AUTOSAR XML (schema 4-0-3)
package /ComponentTypes
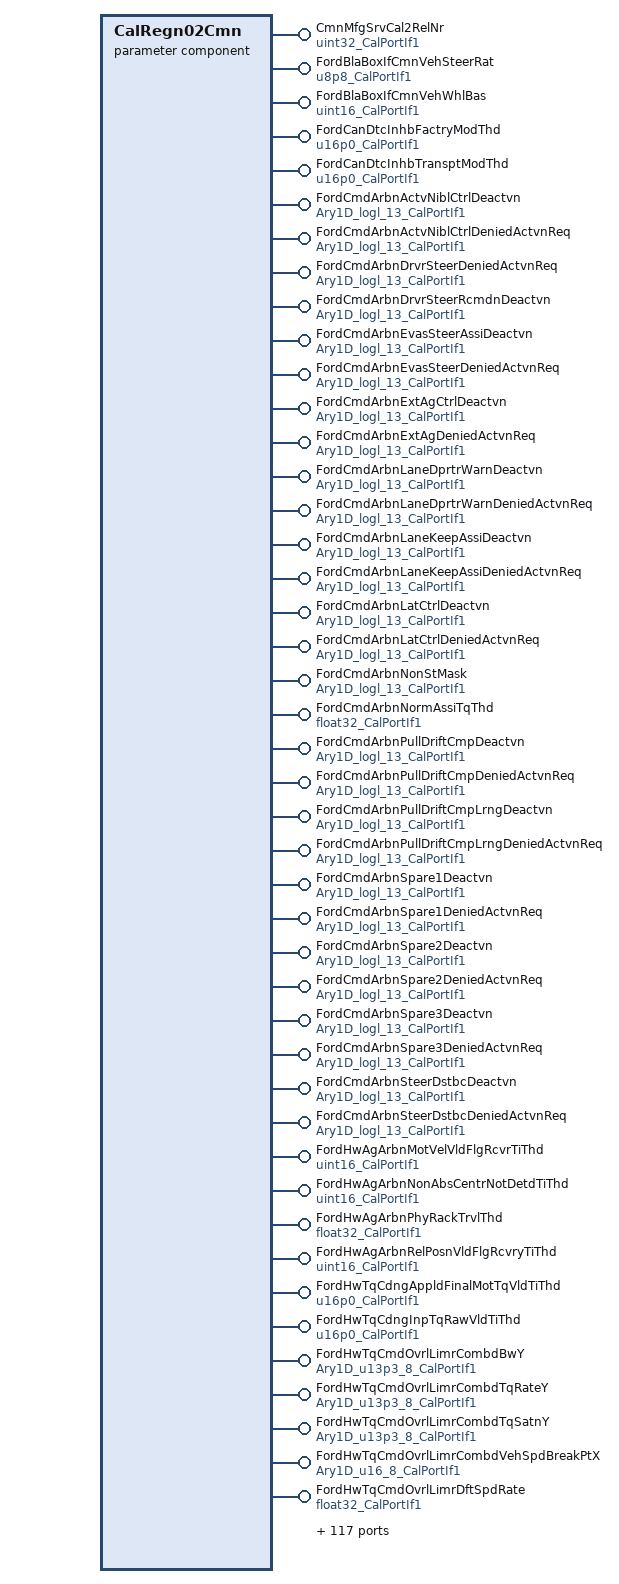
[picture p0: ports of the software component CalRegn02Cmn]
  parameter sw component type CalRegn02Cmn
    161 x provide port:
      CmnMfgSrvCal2RelNr: parameter-provide-com-spec{init-value=0, parameter=Val}, provided-interface=uint32_CalPortIf1
      FordBlaBoxIfCmnVehSteerRat: parameter-provide-com-spec{init-value=0, parameter=Val}, provided-interface=u8p8_CalPortIf1
      FordBlaBoxIfCmnVehWhlBas: parameter-provide-com-spec{init-value=3099, parameter=Val}, provided-interface=uint16_CalPortIf1
      FordCanDtcInhbFactryModThd: parameter-provide-com-spec{init-value=0, parameter=Val}, provided-interface=u16p0_CalPortIf1
      FordCanDtcInhbTransptModThd: parameter-provide-com-spec{init-value=0, parameter=Val}, provided-interface=u16p0_CalPortIf1
      FordCmdArbnActvNiblCtrlDeactvn: parameter-provide-com-spec{init-value=[1, 1, 1, 1, 1, 1, 1, 1, 1, 0, 0, 0, 0], parameter=Ary1D}, provided-interface=Ary1D_logl_13_CalPortIf1
      FordCmdArbnActvNiblCtrlDeniedActvnReq: parameter-provide-com-spec{init-value=[1, 1, 1, 1, 1, 1, 1, 1, 1, 0, 0, 0, 0], parameter=Ary1D}, provided-interface=Ary1D_logl_13_CalPortIf1
      FordCmdArbnDrvrSteerDeniedActvnReq: parameter-provide-com-spec{init-value=[0, 0, 0, 0, 0, 0, 1, 1, 1, 0, 0, 0, 0], parameter=Ary1D}, provided-interface=Ary1D_logl_13_CalPortIf1
      FordCmdArbnDrvrSteerRcmdnDeactvn: parameter-provide-com-spec{init-value=[1, 1, 1, 1, 1, 1, 1, 1, 1, 0, 0, 0, 0], parameter=Ary1D}, provided-interface=Ary1D_logl_13_CalPortIf1
      FordCmdArbnEvasSteerAssiDeactvn: parameter-provide-com-spec{init-value=[1, 1, 1, 1, 1, 1, 1, 1, 1, 0, 0, 0, 0], parameter=Ary1D}, provided-interface=Ary1D_logl_13_CalPortIf1
      FordCmdArbnEvasSteerDeniedActvnReq: parameter-provide-com-spec{init-value=[1, 1, 1, 1, 1, 1, 1, 1, 1, 0, 0, 0, 0], parameter=Ary1D}, provided-interface=Ary1D_logl_13_CalPortIf1
      FordCmdArbnExtAgCtrlDeactvn: parameter-provide-com-spec{init-value=[1, 1, 1, 1, 1, 1, 1, 1, 1, 1, 0, 0, 0], parameter=Ary1D}, provided-interface=Ary1D_logl_13_CalPortIf1
      FordCmdArbnExtAgDeniedActvnReq: parameter-provide-com-spec{init-value=[1, 1, 1, 1, 1, 1, 0, 0, 0, 1, 0, 0, 0], parameter=Ary1D}, provided-interface=Ary1D_logl_13_CalPortIf1
      FordCmdArbnLaneDprtrWarnDeactvn: parameter-provide-com-spec{init-value=[1, 1, 1, 1, 1, 1, 1, 1, 1, 0, 0, 0, 0], parameter=Ary1D}, provided-interface=Ary1D_logl_13_CalPortIf1
      FordCmdArbnLaneDprtrWarnDeniedActvnReq: parameter-provide-com-spec{init-value=[1, 1, 1, 1, 1, 1, 1, 1, 1, 0, 0, 0, 0], parameter=Ary1D}, provided-interface=Ary1D_logl_13_CalPortIf1
      FordCmdArbnLaneKeepAssiDeactvn: parameter-provide-com-spec{init-value=[1, 1, 1, 1, 1, 1, 1, 1, 1, 0, 0, 0, 0], parameter=Ary1D}, provided-interface=Ary1D_logl_13_CalPortIf1
      FordCmdArbnLaneKeepAssiDeniedActvnReq: parameter-provide-com-spec{init-value=[1, 1, 1, 1, 1, 1, 1, 1, 1, 0, 0, 0, 0], parameter=Ary1D}, provided-interface=Ary1D_logl_13_CalPortIf1
      FordCmdArbnLatCtrlDeactvn: parameter-provide-com-spec{init-value=13 x 0, parameter=Ary1D}, provided-interface=Ary1D_logl_13_CalPortIf1
      FordCmdArbnLatCtrlDeniedActvnReq: parameter-provide-com-spec{init-value=13 x 0, parameter=Ary1D}, provided-interface=Ary1D_logl_13_CalPortIf1
      FordCmdArbnNonStMask: parameter-provide-com-spec{init-value=[1, 1, 1, 0, 1, 1, 0, 1, 1, 1, 0, 0, 0], parameter=Ary1D}, provided-interface=Ary1D_logl_13_CalPortIf1
      FordCmdArbnNormAssiTqThd: parameter-provide-com-spec{init-value=0, parameter=Val}, provided-interface=float32_CalPortIf1
      FordCmdArbnPullDriftCmpDeactvn: parameter-provide-com-spec{init-value=[1, 1, 1, 1, 1, 1, 1, 1, 1, 0, 0, 0, 0], parameter=Ary1D}, provided-interface=Ary1D_logl_13_CalPortIf1
      FordCmdArbnPullDriftCmpDeniedActvnReq: parameter-provide-com-spec{init-value=[1, 1, 1, 1, 1, 1, 1, 1, 1, 0, 0, 0, 0], parameter=Ary1D}, provided-interface=Ary1D_logl_13_CalPortIf1
      FordCmdArbnPullDriftCmpLrngDeactvn: parameter-provide-com-spec{init-value=[1, 1, 1, 1, 0, 0, 0, 1, 1, 0, 0, 0, 0], parameter=Ary1D}, provided-interface=Ary1D_logl_13_CalPortIf1
      FordCmdArbnPullDriftCmpLrngDeniedActvnReq: parameter-provide-com-spec{init-value=[1, 1, 1, 1, 0, 0, 0, 1, 1, 0, 0, 0, 0], parameter=Ary1D}, provided-interface=Ary1D_logl_13_CalPortIf1
      FordCmdArbnSpare1Deactvn: parameter-provide-com-spec{init-value=[1, 1, 1, 1, 1, 1, 1, 1, 1, 0, 0, 0, 0], parameter=Ary1D}, provided-interface=Ary1D_logl_13_CalPortIf1
      FordCmdArbnSpare1DeniedActvnReq: parameter-provide-com-spec{init-value=[1, 1, 1, 1, 1, 1, 1, 1, 1, 0, 0, 0, 0], parameter=Ary1D}, provided-interface=Ary1D_logl_13_CalPortIf1
      FordCmdArbnSpare2Deactvn: parameter-provide-com-spec{init-value=[1, 1, 1, 1, 1, 1, 1, 1, 1, 0, 0, 0, 0], parameter=Ary1D}, provided-interface=Ary1D_logl_13_CalPortIf1
      FordCmdArbnSpare2DeniedActvnReq: parameter-provide-com-spec{init-value=[1, 1, 1, 1, 1, 1, 1, 1, 1, 0, 0, 0, 0], parameter=Ary1D}, provided-interface=Ary1D_logl_13_CalPortIf1
      FordCmdArbnSpare3Deactvn: parameter-provide-com-spec{init-value=[1, 1, 1, 1, 1, 1, 1, 1, 1, 0, 0, 0, 0], parameter=Ary1D}, provided-interface=Ary1D_logl_13_CalPortIf1
      FordCmdArbnSpare3DeniedActvnReq: parameter-provide-com-spec{init-value=[1, 1, 1, 1, 1, 1, 1, 1, 1, 0, 0, 0, 0], parameter=Ary1D}, provided-interface=Ary1D_logl_13_CalPortIf1
      FordCmdArbnSteerDstbcDeactvn: parameter-provide-com-spec{init-value=13 x 0, parameter=Ary1D}, provided-interface=Ary1D_logl_13_CalPortIf1
      FordCmdArbnSteerDstbcDeniedActvnReq: parameter-provide-com-spec{init-value=13 x 0, parameter=Ary1D}, provided-interface=Ary1D_logl_13_CalPortIf1
      FordHwAgArbnMotVelVldFlgRcvrTiThd: parameter-provide-com-spec{init-value=30000, parameter=Val}, provided-interface=uint16_CalPortIf1
      FordHwAgArbnNonAbsCentrNotDetdTiThd: parameter-provide-com-spec{init-value=30000, parameter=Val}, provided-interface=uint16_CalPortIf1
      FordHwAgArbnPhyRackTrvlThd: parameter-provide-com-spec{init-value=65535, parameter=Val}, provided-interface=float32_CalPortIf1
      FordHwAgArbnRelPosnVldFlgRcvryTiThd: parameter-provide-com-spec{init-value=0, parameter=Val}, provided-interface=uint16_CalPortIf1
      FordHwTqCdngAppldFinalMotTqVldTiThd: parameter-provide-com-spec{init-value=0, parameter=Val}, provided-interface=u16p0_CalPortIf1
      FordHwTqCdngInpTqRawVldTiThd: parameter-provide-com-spec{init-value=0, parameter=Val}, provided-interface=u16p0_CalPortIf1
      FordHwTqCmdOvrlLimrCombdBwY: parameter-provide-com-spec{init-value=8 x 0, parameter=Ary1D}, provided-interface=Ary1D_u13p3_8_CalPortIf1
      FordHwTqCmdOvrlLimrCombdTqRateY: parameter-provide-com-spec{init-value=8 x 64, parameter=Ary1D}, provided-interface=Ary1D_u13p3_8_CalPortIf1
      FordHwTqCmdOvrlLimrCombdTqSatnY: parameter-provide-com-spec{init-value=8 x 0, parameter=Ary1D}, provided-interface=Ary1D_u13p3_8_CalPortIf1
      FordHwTqCmdOvrlLimrCombdVehSpdBreakPtX: parameter-provide-com-spec{init-value=[0, 15, 60, 100, 150, 180, 200, 250], parameter=Ary1D}, provided-interface=Ary1D_u16_8_CalPortIf1
      FordHwTqCmdOvrlLimrDftSpdRate: parameter-provide-com-spec{init-value=40, parameter=Val}, provided-interface=float32_CalPortIf1
      FordHwTqCmdOvrlLimrDftSpdRcvrRate: parameter-provide-com-spec{init-value=40, parameter=Val}, provided-interface=float32_CalPortIf1
      FordHwTqCmdOvrlLimrLkaBwY: parameter-provide-com-spec{init-value=8 x 0, parameter=Ary1D}, provided-interface=Ary1D_u13p3_8_CalPortIf1
      FordHwTqCmdOvrlLimrLkaTqRateY: parameter-provide-com-spec{init-value=8 x 40, parameter=Ary1D}, provided-interface=Ary1D_u13p3_8_CalPortIf1
      FordHwTqCmdOvrlLimrLkaTqSatnY: parameter-provide-com-spec{init-value=8 x 0, parameter=Ary1D}, provided-interface=Ary1D_u13p3_8_CalPortIf1
      FordHwTqCmdOvrlLimrVehSpdBreakPtX: parameter-provide-com-spec{init-value=[0, 15, 60, 100, 150, 180, 200, 250], parameter=Ary1D}, provided-interface=Ary1D_u16_8_CalPortIf1
      FordMotTqCmdOvrlLimrDftSpdRate: parameter-provide-com-spec{init-value=40, parameter=Val}, provided-interface=float32_CalPortIf1
      FordMotTqCmdOvrlLimrDftSpdRcvrRate: parameter-provide-com-spec{init-value=40, parameter=Val}, provided-interface=float32_CalPortIf1
      FordMotTqCmdOvrlLimrHiFrqMonrActvNiblCtrlDcTqTrendThd: parameter-provide-com-spec{init-value=1, parameter=Val}, provided-interface=float32_CalPortIf1
      FordMotTqCmdOvrlLimrHiFrqMonrActvNiblCtrlLoFrqTiThd: parameter-provide-com-spec{init-value=0.1, parameter=Val}, provided-interface=float32_CalPortIf1
      FordMotTqCmdOvrlLimrHiFrqMonrActvNiblCtrlMaxMotTq: parameter-provide-com-spec{init-value=5, parameter=Val}, provided-interface=float32_CalPortIf1
      FordMotTqCmdOvrlLimrHiFrqMonrLaneDprtrWarnDcTqTrendThd: parameter-provide-com-spec{init-value=1.5, parameter=Val}, provided-interface=float32_CalPortIf1
      FordMotTqCmdOvrlLimrHiFrqMonrLaneDprtrWarnLoFrqTiThd: parameter-provide-com-spec{init-value=0.033, parameter=Val}, provided-interface=float32_CalPortIf1
      FordMotTqCmdOvrlLimrHiFrqMonrLaneDprtrWarnMaxMotTq: parameter-provide-com-spec{init-value=5.5, parameter=Val}, provided-interface=float32_CalPortIf1
      FordMotTqCmdOvrlLimrHiFrqMonrTqTrendAlpha: parameter-provide-com-spec{init-value=1, parameter=Val}, provided-interface=float32_CalPortIf1
      FordMotTqCmdOvrlLimrHiFrqMonrZeroBandTq: parameter-provide-com-spec{init-value=1, parameter=Val}, provided-interface=float32_CalPortIf1
      FordMotTqCmdOvrlLimrHwVelLoPassFrq: parameter-provide-com-spec{init-value=0, parameter=Val}, provided-interface=float32_CalPortIf1
      FordMotTqCmdOvrlLimrLatCtrlBwY: parameter-provide-com-spec=Val, provided-interface=Ary1D_s5p10_8_CalPortIf1
      FordMotTqCmdOvrlLimrLatCtrlTqRateY: parameter-provide-com-spec{init-value=8 x 5, parameter=Ary1D}, provided-interface=Ary1D_s16_8_CalPortIf1
      FordMotTqCmdOvrlLimrLatCtrlTqSatnY: parameter-provide-com-spec{init-value=8 x 0, parameter=Ary1D}, provided-interface=Ary1D_s16_8_CalPortIf1
      FordMotTqCmdOvrlLimrLatCtrlVehSpdBreakPtX: parameter-provide-com-spec{init-value=[0, 1920, 7680, 12800, 19200, 23040, 25600, 32000], parameter=Ary1D}, provided-interface=Ary1D_u9p7_8_CalPortIf1
      FordMotTqCmdOvrlLimrPullDriftCmpTqRateY: parameter-provide-com-spec{init-value=8 x 1, parameter=Ary1D}, provided-interface=Ary1D_s16_8_CalPortIf1
      FordMotTqCmdOvrlLimrPullDriftCmpTqSatnY: parameter-provide-com-spec{init-value=8 x 3, parameter=Ary1D}, provided-interface=Ary1D_s16_8_CalPortIf1
      FordMotTqCmdOvrlLimrPullDriftCmpVehSpdBreakPtX: parameter-provide-com-spec{init-value=[0, 15, 60, 100, 150, 180, 200, 250], parameter=Ary1D}, provided-interface=Ary1D_u16_8_CalPortIf1
      FordMotTqCmdOvrlLimrSteerReactnLimrCombAmpVehSpdLimX: parameter-provide-com-spec{init-value=8 x 0, parameter=Ary1D}, provided-interface=Ary1D_u16_8_CalPortIf1
      FordMotTqCmdOvrlLimrSteerReactnLimrCombAmpVehSpdLimY: parameter-provide-com-spec{init-value=[0, 15, 40, 70, 100, 150, 200, 250], parameter=Ary1D}, provided-interface=Ary1D_u16_8_CalPortIf1
      FordMotTqCmdOvrlLimrSteerReactnLimrCombdAmpOvrrun: parameter-provide-com-spec{init-value=0, parameter=Val}, provided-interface=float32_CalPortIf1
      FordMotTqCmdOvrlLimrSteerReactnLimrCombdAmpRcvry: parameter-provide-com-spec{init-value=0.5, parameter=Val}, provided-interface=float32_CalPortIf1
      FordMotTqCmdOvrlLimrSteerReactnLimrCombdFixdOvrrunRampRate: parameter-provide-com-spec{init-value=8, parameter=Val}, provided-interface=float32_CalPortIf1
      FordMotTqCmdOvrlLimrSteerReactnLimrCombdLimHys: parameter-provide-com-spec{init-value=0.05, parameter=Val}, provided-interface=float32_CalPortIf1
      FordMotTqCmdOvrlLimrSteerReactnLimrCombdLimrHwVelY: parameter-provide-com-spec{init-value=[[-20, 10, 20, 30, 80, 100, 100, 100, 100], [-20, 10, 20, 30, 80, 100, 100, 100, 100], [-20, 10, 20, 20, 80, 100, 100, 100, 100], [-20, 10, 20, 20, 80, 100, 100, 100, 100], [-40, 5, 10, 15, 60, 80, 80, 80, 80], [-40, 0, 5, 10, 30, 40, 40, 40, 40], [-40, 0, 5, 10, 20, 30, 30, 30, 30], [-40, 0, 5, 10, 20, 30, 30, 30, 30]], parameter=Ary2D}, provided-interface=Ary2D_s16_8_9_CalPortIf1
      FordMotTqCmdOvrlLimrSteerReactnLimrCombdLimrVehSpd: parameter-provide-com-spec{init-value=[0, 15, 40, 70, 100, 150, 200, 250], parameter=Ary1D}, provided-interface=Ary1D_u16_8_CalPortIf1
      FordMotTqCmdOvrlLimrSteerReactnLimrCombdLimTqX: parameter-provide-com-spec{init-value=8 x [-6, -5, -4, -2, 0, 2, 4, 5, 6], parameter=Ary2D}, provided-interface=Ary2D_s16_8_9_CalPortIf1
      FordMotTqCmdOvrlLimrSteerReactnLimrCombdRcvryIdealRampRate: parameter-provide-com-spec{init-value=0, parameter=Val}, provided-interface=float32_CalPortIf1
      FordMotTqCmdOvrlLimrSteerReactnLimrCombdRcvryRampRateStg1: parameter-provide-com-spec{init-value=20, parameter=Val}, provided-interface=float32_CalPortIf1
      FordMotTqCmdOvrlLimrSteerReactnLimrCombdRcvryRampRateStg2: parameter-provide-com-spec{init-value=40, parameter=Val}, provided-interface=float32_CalPortIf1
      FordMotTqCmdOvrlLimrSteerReactnLimrCombOvrrunRampRateHwVelErrX: parameter-provide-com-spec{init-value=[0, 25, 50, 100, 170, 250], parameter=Ary1D}, provided-interface=Ary1D_u16_6_CalPortIf1
      FordMotTqCmdOvrlLimrSteerReactnLimrCombOvrrunRampRateOutY: parameter-provide-com-spec{init-value=[0, 35, 70, 130, 300, 600], parameter=Ary1D}, provided-interface=Ary1D_u16_6_CalPortIf1
      FordVehSpdArbnDrvnWhl: parameter-provide-com-spec{init-value=0, parameter=Logl}, provided-interface=boolean_CalPortIf1
      FordVehSpdArbnTireCircumMax: parameter-provide-com-spec{init-value=2500, parameter=Val}, provided-interface=uint16_CalPortIf1
      FordVehSpdArbnTireCircumMin: parameter-provide-com-spec{init-value=1500, parameter=Val}, provided-interface=uint16_CalPortIf1
      FordVltgIfActvParkAssiAsscTqMin: parameter-provide-com-spec{init-value=0, parameter=Val}, provided-interface=float32_CalPortIf1
      FordVltgIfEpsBattCurrLim: parameter-provide-com-spec{init-value=0, parameter=Val}, provided-interface=float32_CalPortIf1
      FordVltgIfEPSBattVltgDifThd: parameter-provide-com-spec{init-value=5, parameter=Val}, provided-interface=float32_CalPortIf1
      FordVltgIfEpsCurrLim: parameter-provide-com-spec{init-value=40, parameter=Val}, provided-interface=float32_CalPortIf1
      FordVltgIfEvasSteerAssiTqMin: parameter-provide-com-spec{init-value=90, parameter=Val}, provided-interface=float32_CalPortIf1
      FordVltgIfFeatThdStsTiThd: parameter-provide-com-spec{init-value=1000, parameter=Val}, provided-interface=uint16_CalPortIf1
      FordVltgIfHiVltgAssiRampDwnRate: parameter-provide-com-spec{init-value=50, parameter=Val}, provided-interface=float32_CalPortIf1
      FordVltgIfHiVltgAssiRampUpRate: parameter-provide-com-spec{init-value=50, parameter=Val}, provided-interface=float32_CalPortIf1
      FordVltgIfHiVltgInhbTiMax: parameter-provide-com-spec{init-value=100, parameter=Val}, provided-interface=uint16_CalPortIf1
      FordVltgIfHiVltgNoAssiRampDwnRate: parameter-provide-com-spec{init-value=50, parameter=Val}, provided-interface=float32_CalPortIf1
      FordVltgIfHiVltgNoAssiRcvrTiMax: parameter-provide-com-spec{init-value=2000, parameter=Val}, provided-interface=uint32_CalPortIf1
      FordVltgIfHiVltgRcvrTiMax: parameter-provide-com-spec{init-value=500, parameter=Val}, provided-interface=uint32_CalPortIf1
      FordVltgIfHiVltgThdHi: parameter-provide-com-spec{init-value=19, parameter=Val}, provided-interface=float32_CalPortIf1
      FordVltgIfHiVltgThdLo: parameter-provide-com-spec{init-value=18, parameter=Val}, provided-interface=float32_CalPortIf1
      FordVltgIfInhbBattVltgDiagcTiThd: parameter-provide-com-spec{init-value=1000, parameter=Val}, provided-interface=uint16_CalPortIf1
      FordVltgIfLaneCentrAssiTqMin: parameter-provide-com-spec{init-value=90, parameter=Val}, provided-interface=float32_CalPortIf1
      FordVltgIfLaneDprtrWarnAsscTqMin: parameter-provide-com-spec{init-value=90, parameter=Val}, provided-interface=float32_CalPortIf1
      FordVltgIfLkaAsscTqMin: parameter-provide-com-spec{init-value=90, parameter=Val}, provided-interface=float32_CalPortIf1
      FordVltgIfLoVltgAssiRampDwnRate: parameter-provide-com-spec{init-value=50, parameter=Val}, provided-interface=float32_CalPortIf1
      FordVltgIfLoVltgAssiRampUpRate: parameter-provide-com-spec{init-value=50, parameter=Val}, provided-interface=float32_CalPortIf1
      FordVltgIfLoVltgAssiScar: parameter-provide-com-spec{init-value=0.4, parameter=Val}, provided-interface=float32_CalPortIf1
      FordVltgIfLoVltgInhbTiMax: parameter-provide-com-spec{init-value=100, parameter=Val}, provided-interface=uint32_CalPortIf1
      FordVltgIfLoVltgNoAssiRampDwnRate: parameter-provide-com-spec{init-value=50, parameter=Val}, provided-interface=float32_CalPortIf1
      FordVltgIfLoVltgNoAssiRcvrTiMax: parameter-provide-com-spec{init-value=2000, parameter=Val}, provided-interface=uint16_CalPortIf1
      FordVltgIfLoVltgRcvrTiMax: parameter-provide-com-spec{init-value=500, parameter=Val}, provided-interface=uint32_CalPortIf1
      FordVltgIfLoVltgThdHi: parameter-provide-com-spec{init-value=11, parameter=Val}, provided-interface=float32_CalPortIf1
      FordVltgIfLoVltgThdLo: parameter-provide-com-spec{init-value=7, parameter=Val}, provided-interface=float32_CalPortIf1
      FordVltgIfLoVltgThdMid: parameter-provide-com-spec{init-value=10, parameter=Val}, provided-interface=float32_CalPortIf1
      FordVltgIfLoVltgThdMidToLoTiMax: parameter-provide-com-spec{init-value=1000, parameter=Val}, provided-interface=uint32_CalPortIf1
      FordVltgIfLoVltgTqScaDwnRate: parameter-provide-com-spec{init-value=50, parameter=Val}, provided-interface=float32_CalPortIf1
      FordVltgIfLoVltgTqScagFac: parameter-provide-com-spec{init-value=0.25, parameter=Val}, provided-interface=float32_CalPortIf1
      FordVltgIfLoVltgTqScaUpRate: parameter-provide-com-spec{init-value=50, parameter=Val}, provided-interface=float32_CalPortIf1
      FordVltgIfTrfcJamAsscTqMin: parameter-provide-com-spec{init-value=90, parameter=Val}, provided-interface=float32_CalPortIf1
      FordVltgIfTrlrBackupAssiTqMin: parameter-provide-com-spec{init-value=90, parameter=Val}, provided-interface=float32_CalPortIf1
      FordVltgIfVehBattCircR: parameter-provide-com-spec{init-value=0.1, parameter=Val}, provided-interface=float32_CalPortIf1
      FullAssiRampUpRate: parameter-provide-com-spec{init-value=1, parameter=Val}, provided-interface=float32_CalPortIf1
      InitLimpHomeRamp: parameter-provide-com-spec{init-value=1, parameter=Val}, provided-interface=float32_CalPortIf1
      InitLimpHomeScar: parameter-provide-com-spec{init-value=0, parameter=Val}, provided-interface=float32_CalPortIf1
      LimdAssiRamp: parameter-provide-com-spec{init-value=1, parameter=Val}, provided-interface=float32_CalPortIf1
      LimdAssiRampUpRate: parameter-provide-com-spec{init-value=1, parameter=Val}, provided-interface=float32_CalPortIf1
      LimdAssiRampUpRateFaild: parameter-provide-com-spec{init-value=1, parameter=Val}, provided-interface=float32_CalPortIf1
      LimdAssiScar: parameter-provide-com-spec{init-value=0, parameter=Val}, provided-interface=float32_CalPortIf1
      LoaMgrCurrIvtrMtgtnRate: parameter-provide-com-spec{init-value=1, parameter=Val}, provided-interface=float32_CalPortIf1
      LoaMgrCurrIvtrMtgtnSca: parameter-provide-com-spec{init-value=1, parameter=Val}, provided-interface=float32_CalPortIf1
      LoaMgrCurrMeasMtgtnRate: parameter-provide-com-spec{init-value=1, parameter=Val}, provided-interface=float32_CalPortIf1
      LoaMgrCurrMeasMtgtnSca: parameter-provide-com-spec{init-value=1, parameter=Val}, provided-interface=float32_CalPortIf1
      LoaMgrIvtrMtgtnRate: parameter-provide-com-spec{init-value=1, parameter=Val}, provided-interface=float32_CalPortIf1
      LoaMgrIvtrMtgtnSca: parameter-provide-com-spec{init-value=1, parameter=Val}, provided-interface=float32_CalPortIf1
      LoaMgrLimdStRate: parameter-provide-com-spec{init-value=1, parameter=Val}, provided-interface=float32_CalPortIf1
      LoaMgrLimdStSca: parameter-provide-com-spec{init-value=1, parameter=Val}, provided-interface=float32_CalPortIf1
      LoaMgrMotAgMtgtnRate: parameter-provide-com-spec{init-value=1, parameter=Val}, provided-interface=float32_CalPortIf1
      LoaMgrMotAgMtgtnSca: parameter-provide-com-spec{init-value=1, parameter=Val}, provided-interface=float32_CalPortIf1
      MotRplCoggCfgMotAgTiDly: parameter-provide-com-spec{init-value=0, parameter=Val}, provided-interface=float32_CalPortIf1
      MotRplCoggCfgMotCurrDaxRplBilnrSeln: parameter-provide-com-spec{init-value=[0, 1280, 3200, 6400, 7680, 9600, 11520, 12800, 14080, 16000], parameter=Ary1D}, provided-interface=Ary1D_u9p7_10_CalPortIf1
      MotRplCoggCfgMotCurrQaxRpl: parameter-provide-com-spec{init-value=[0, 1280, 3200, 6400, 7680, 9600, 12800, 13440, 14080, 15360, 16000, 17280], parameter=Ary1D}, provided-interface=Ary1D_u9p7_12_CalPortIf1
      MotRplCoggCfgMotTqCmdCurrRgltrBwCmpMgnY: parameter-provide-com-spec{init-value=20 x 8 x 0, parameter=Ary2D}, provided-interface=Ary2D_u3p13_20_8_CalPortIf1
      MotRplCoggCfgMotTqCmdCurrRgltrBwCmpPhaY: parameter-provide-com-spec{init-value=20 x 8 x 0, parameter=Ary2D}, provided-interface=Ary2D_u0p16_20_8_CalPortIf1
      MotRplCoggCfgMotTqCmdCurrRgltrBwCmpX: parameter-provide-com-spec{init-value=[0, 1024, 2048, 4096, 6144, 8192, 9216, 10240], parameter=Ary1D}, provided-interface=Ary1D_u5p11_8_CalPortIf1
      MotRplCoggCfgMotTqRplOrder1X: parameter-provide-com-spec{init-value=10 x 12 x 0, parameter=Ary2D}, provided-interface=Ary2D_s1p14_10_12_CalPortIf1
      MotRplCoggCfgMotTqRplOrder1Y: parameter-provide-com-spec{init-value=10 x 12 x 0, parameter=Ary2D}, provided-interface=Ary2D_s1p14_10_12_CalPortIf1
      MotRplCoggCfgMotTqRplOrder2X: parameter-provide-com-spec{init-value=10 x 12 x 0, parameter=Ary2D}, provided-interface=Ary2D_s1p14_10_12_CalPortIf1
      MotRplCoggCfgMotTqRplOrder2Y: parameter-provide-com-spec{init-value=10 x 12 x 0, parameter=Ary2D}, provided-interface=Ary2D_s1p14_10_12_CalPortIf1
      MotRplCoggCfgMotTqRplOrder3X: parameter-provide-com-spec{init-value=10 x 12 x 0, parameter=Ary2D}, provided-interface=Ary2D_s1p14_10_12_CalPortIf1
      MotRplCoggCfgMotTqRplOrder3Y: parameter-provide-com-spec{init-value=10 x 12 x 0, parameter=Ary2D}, provided-interface=Ary2D_s1p14_10_12_CalPortIf1
      MotRplCoggCfgMotVelBilnrSeln: parameter-provide-com-spec{init-value=[0, 100, 114, 303, 800, 1200, 2600, 3200, 3700, 4200, 5000, 6000, 7200, 7500, 8000, 8500, 9000, 9500, 10000, 11000], parameter=Ary1D}, provided-interface=Ary1D_u16p0_20_CalPortIf1
      MotRplCoggCmdHrmncOrder1Elec: parameter-provide-com-spec{init-value=6, parameter=Val}, provided-interface=uint8_CalPortIf1
      MotRplCoggCmdHrmncOrder2Elec: parameter-provide-com-spec{init-value=12, parameter=Val}, provided-interface=uint8_CalPortIf1
      MotRplCoggCmdHrmncOrder3Elec: parameter-provide-com-spec{init-value=18, parameter=Val}, provided-interface=uint8_CalPortIf1
      NormLimpHomeRamp: parameter-provide-com-spec{init-value=1, parameter=Val}, provided-interface=float32_CalPortIf1
      NormLimpHomeScar: parameter-provide-com-spec{init-value=0, parameter=Val}, provided-interface=float32_CalPortIf1
      NxtrCalIdsCal1DevlpAuthor: parameter-provide-com-spec{init-value=6 x 0, parameter=Ary1D}, provided-interface=Ary1D_u08_6_CalPortIf1
      NxtrCalIdsCal1DevlpDesc: parameter-provide-com-spec{init-value=48 x 0, parameter=Ary1D}, provided-interface=Ary1D_u08_48_CalPortIf1
      NxtrCalIdsCal1DevlpRelNr: parameter-provide-com-spec{init-value=0, parameter=Val}, provided-interface=uint32_CalPortIf1
      NxtrCalIdsCal1DevlpRelSt: parameter-provide-com-spec{init-value=0, parameter=Val}, provided-interface=uint8_CalPortIf1
      NxtrCalIdsCal1DevlpTiStamp: parameter-provide-com-spec{init-value=0, parameter=Val}, provided-interface=uint32_CalPortIf1
      NxtrCalIdsCal1DevlpVers: parameter-provide-com-spec{init-value=0, parameter=Val}, provided-interface=uint8_CalPortIf1
      ShtdwnRamp: parameter-provide-com-spec{init-value=1, parameter=Val}, provided-interface=float32_CalPortIf1
